# max32657 register map
Vendor: Maxim-Integrated; Series: ARMCM33; File version: 1.1
CPU: CM4 r2p1, little endian, MPU, FPU, 3 interrupt priority bits
Registers are 32-bit, read-write, reset 0x0 unless marked. A register's access mark holds for its fields unless they carry their own. Offsets are from the block's base; [hi:lo] are bit positions; lines under a group give offsets from that group; {n}, {i} and the like mark numbered series.

## FLC — Flash Memory Control.
Base 0x50029000; register names take the prefix FLSH_
0x00 ADDR — Flash Write Address.
  [31:0] ADDR — Address for next operation.
0x04 CLKDIV reset 0x32 — Flash Clock Divide. The clock (PLL0) is divided by this value to generate a 1 MHz clock for Flash controller.
  [7:0] CLKDIV — Flash Clock Divide. The clock is divided by this value to generate a 1MHz clock for flash controller.
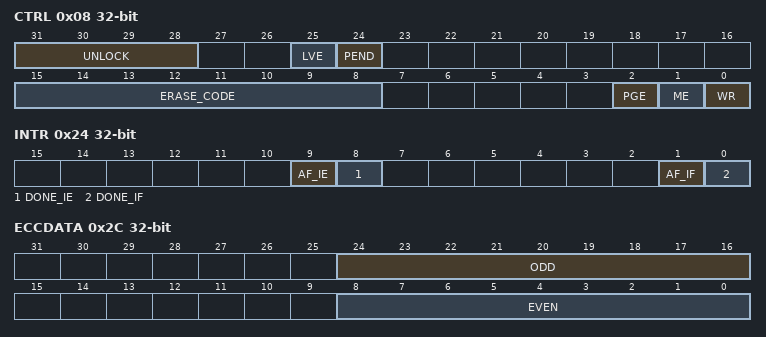
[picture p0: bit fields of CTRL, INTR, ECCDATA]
0x08 CTRL — Flash Control Register.
  [31:28] UNLOCK — Flash Unlock. The correct unlock code must be written to these four bits before any Flash write or erase operation is allowed.
    2=unlocked (Flash Unlocked.); 3=locked (Flash Locked.)
  [25] LVE — Low Voltage enable.
  [24] PEND ro — Flash Pending. When Flash operation is in progress (busy), Flash reads and writes will fail. When PEND is set, write to all Flash registers, with exception of the Flash interrupt register, are ignored.
    0=idle; 1=busy
  [15:8] ERASE_CODE — Erase Code. The ERASE_CODE must be set up property before erase operation can be initiated. These bits are automatically cleared after the operation is complete.
    0=nop (No operation.); 85=erasePage (Enable Page Erase.); 170=eraseAll (Enable Mass Erase. The debug port must be enabled.)
  [2] PGE — Page Erase. This bit is automatically cleared after the operation.
    0=complete (No operation/complete.); 1=Start operation
  [1] ME — Mass Erase. This bit is automatically cleared after the operation.
    0=complete (No operation/complete.); 1=Start operation
  [0] WR — Write. This bit is automatically cleared after the operation.
    0=complete (No operation/complete.); 1=Start operation
0x24 INTR — Flash Interrupt Register.
  [9] AF_IE — Flash Done Interrupt Enable.
    0=disable; 1=enable
  [8] DONE_IE — Flash Done Interrupt Enable.
    0=disable; 1=enable
  [1] AF_IF — Flash Access Fail. This bit is set when an attempt is made to write the flash while the flash is busy or the flash is locked. This bit can only be set to 1 by hardware.
    0=noError (No Failure.); 1=error (Failure occurs.)
  [0] DONE_IF — Flash Done Interrupt. This bit is set to 1 upon Flash write or erase completion.
    0=inactive (No interrupt is pending.); 1=pending (An interrupt is pending.)
0x2C ECCDATA
  [24:16] ODD — Error Correction Code Even Data.
  [8:0] EVEN — Error Correction Code Odd Data.
{0x30+4i} DATA[{i}] (i=0..3) — Flash Write Data.
  [31:0] DATA — Data next operation.
0x40 ACTRL wo — Access Control Register. Writing the ACTRL register with the following values in the order shown, allows read and write access to the system and user Information block: pflc-actrl = 0x3a7f5ca3; pflc-actrl = 0xa1e34f20; pflc-actrl = 0x9608b2c1. When unlocked, a write of any word will disable access to system and user information block. Readback of this register is always zero.
  [31:0] ACTRL — Access control.

## ICC — Instruction Cache Controller Registers
Base 0x5002A000
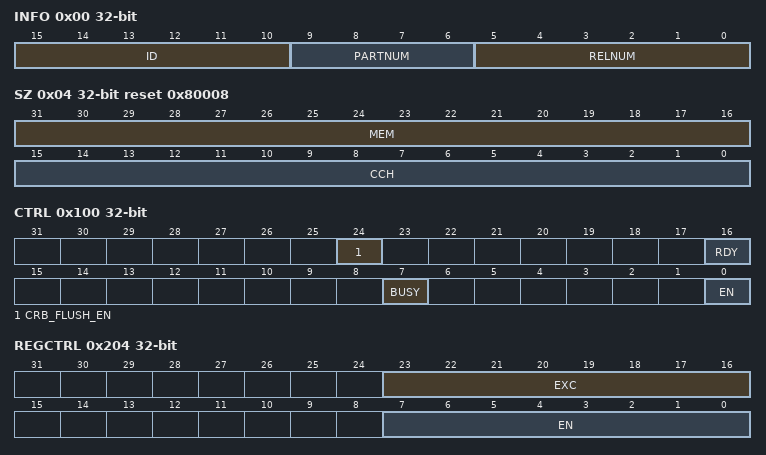
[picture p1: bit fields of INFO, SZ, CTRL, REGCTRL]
0x00 INFO ro — Cache ID Register.
  [15:10] ID — Cache ID. This field reflects the value of the C_ID_CACHEID configuration parameter.
  [9:6] PARTNUM — Part Number. This field reflects the value of C_ID_PART_NUMBER configuration parameter.
  [5:0] RELNUM — Release Number. Identifies the RTL release version.
0x04 SZ ro reset 0x80008 — Memory Configuration Register.
  [31:16] MEM — Main Memory Size. Indicates the total size, in units of 128 Kbytes, of code memory accessible to the cache controller.
  [15:0] CCH — Cache Size. Indicates total size in Kbytes of cache.
0x100 CTRL — Cache Control and Status Register.
  [24] CRB_FLUSH_EN — Coherent Read Buffer flush enable. Write 1 to flush the coherent read buffer.
  [16] RDY ro — Cache Ready flag. Cleared by hardware when at any time the cache as a whole is invalidated (including a system reset). When this bit is 0, the cache is effectively in bypass mode (instruction fetches will come from main memory or from the line fill buffer). Set by hardware when the invalidate operation is complete and the cache is ready.
    0=notReady; 1=ready
  [7] BUSY ro — Cache Busy. Read-only status bit set by hardware while a cache operation (invalidate or flush) is in progress.
  [0] EN — Cache Enable. Controls whether the cache is bypassed or is in use. Changing the state of this bit will cause the instruction cache to be flushed and its contents invalidated.
    0=dis (Cache Bypassed. Instruction data is stored in the line fill buffer but is not written to main cache memory array.); 1=en (Cache Enabled.)
0x200 WAY — Cache Way Control Register.
  [2:0] WAY — Number of cache way, default is always 2. Allowed values are 1,2,4.
0x204 REGCTRL — Regional Control Register.
  [23:16] EXC — Cache the data only if the TAG content is excluded in the high and low bound.
  [7:0] EN — Enable the regional high andlow bound compare, cache the data only if the TAG content between the high and low bound.
{0x208+8i} REGION[{i}] (i=0..3) group — Regional Low and High Bound Registers.
  0x00 LBOUND — Regional Low Bound Register.
    [31:0] BOUND — Low Bound.
  0x04 HBOUND — Regional High Bound Register.
    [31:0] BOUND — High Bound.
0x300 PFMCTRL — Performance Control Register.
  [0] EN — Enable performance counter. Clear to 0 when AHB access counter reach 0.
0x304 PFMCNT — Performance Counter Register.
  [31:0] CNT — Write the total AHB access counter. Read the current performance hit count.
0x700 INVALIDATE — Invalidate All Registers.
  [31:0] INVALID — Invalidate.
